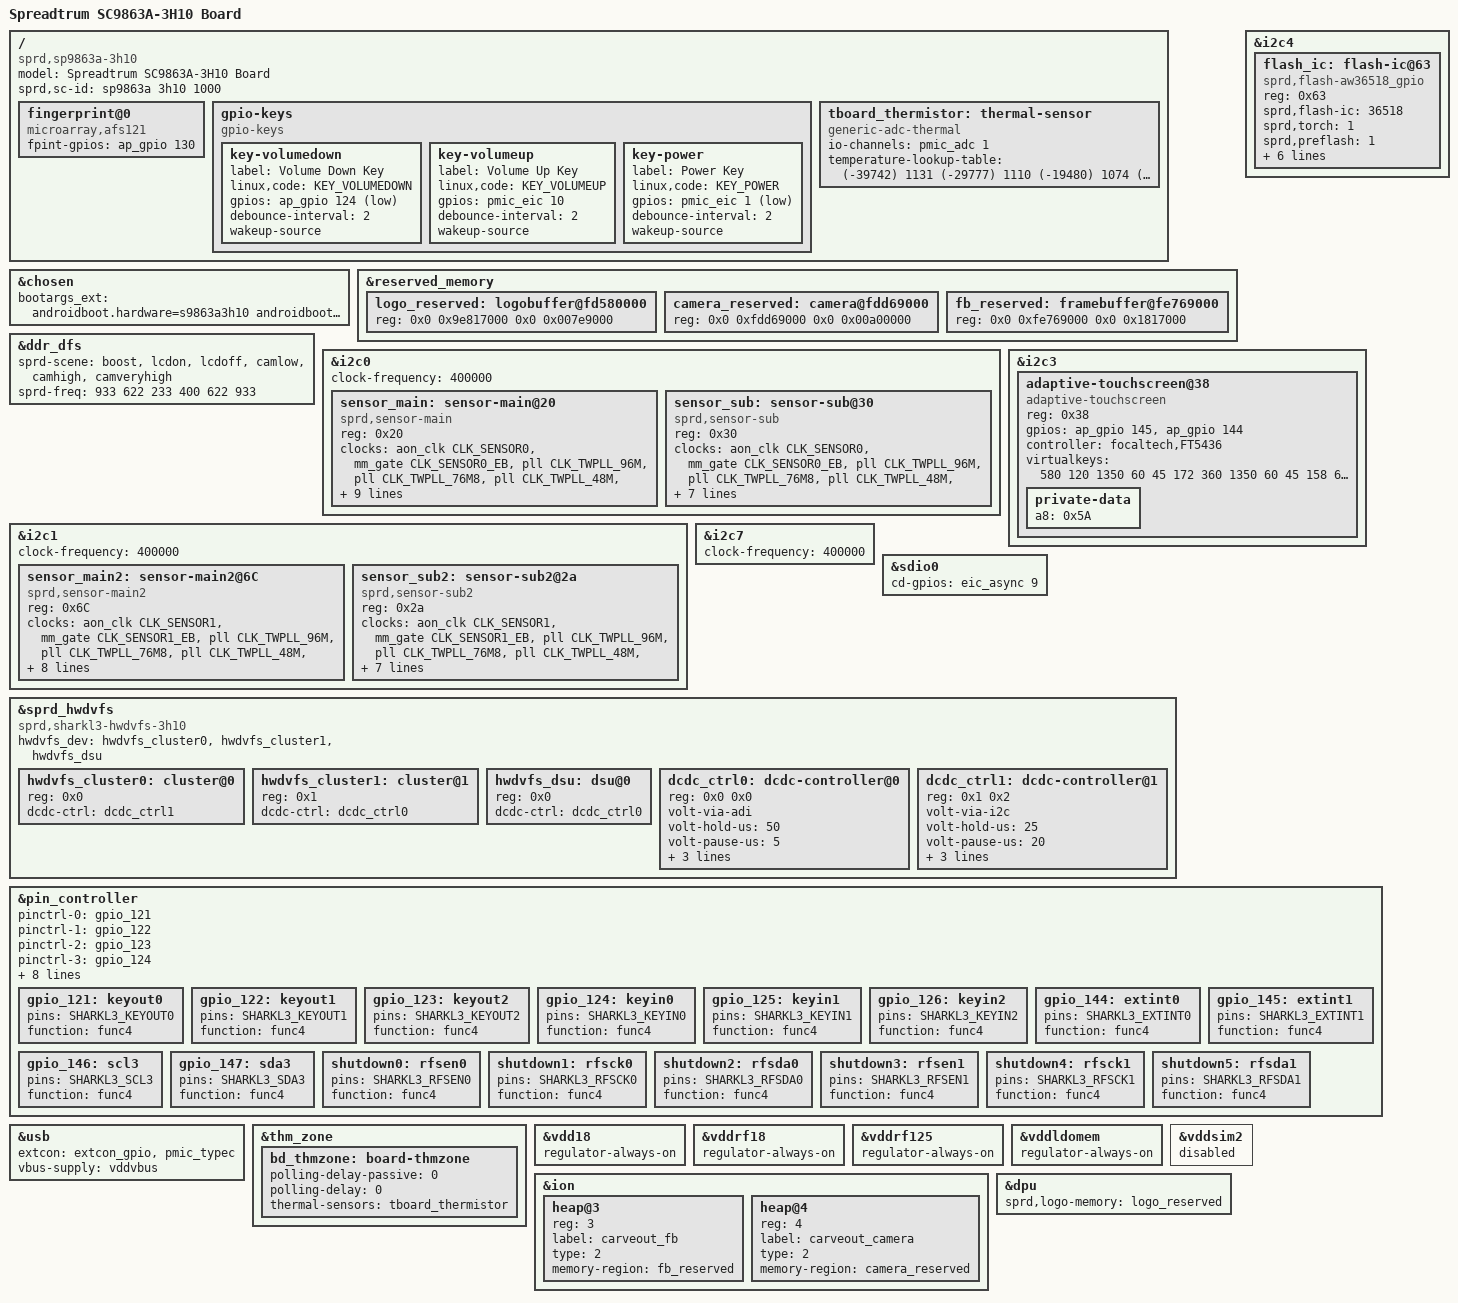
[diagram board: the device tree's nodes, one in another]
/dts-v1/;
/plugin/;

#include <dt-bindings/input/input.h>
#include <dt-bindings/gpio/gpio.h>
#include <dt-bindings/clock/sprd,sc9863a-clk.h>
/ {
	model = "Spreadtrum SC9863A-3H10 Board";
	compatible = "sprd,sp9863a-3h10", "sprd,sc9863a";
	sprd,sc-id = "sp9863a 3h10 1000";

	fragment {
		target-path = "/";
		__overlay__ {
			fingerprint@0 {
				compatible = "microarray,afs121";
				fpint-gpios = <&ap_gpio 130 0>;
			};

			gpio-keys {
				compatible = "gpio-keys";

				key-volumedown {
					label = "Volume Down Key";
					linux,code = <KEY_VOLUMEDOWN>;
					gpios = <&ap_gpio 124 GPIO_ACTIVE_LOW>;
					debounce-interval = <2>;
					wakeup-source;
				};

				key-volumeup {
					label = "Volume Up Key";
					linux,code = <KEY_VOLUMEUP>;
					gpios = <&pmic_eic 10 GPIO_ACTIVE_HIGH>;
					debounce-interval = <2>;
					wakeup-source;
				};

				key-power {
					label = "Power Key";
					linux,code = <KEY_POWER>;
					gpios = <&pmic_eic 1 GPIO_ACTIVE_LOW>;
					debounce-interval = <2>;
					wakeup-source;
				};
			};

			tboard_thermistor:thermal-sensor {
				compatible = "generic-adc-thermal";
				#thermal-sensor-cells = <0>;
				io-channels = <&pmic_adc 1>;
				io-channel-names = "sensor-channel";
				temperature-lookup-table = <	(-39742) 1131
								(-29777) 1110
								(-19480) 1074
								(-4679) 983
								10110 838
								24805 654
								44922 413
								54903 316
								64895 238
								74884 178
								84883 133
								94883 100
								104880 75
								114889 57
								124872 43 >;
			};
		};
	};
};

&chosen {
	bootargs_ext = "androidboot.hardware=s9863a3h10 androidboot.dtbo_idx=0";
};

&reserved_memory {

	logo_reserved: logobuffer@fd580000{
		reg = <0x0 0xfd580000 0x0 0x007e9000>;
	};

	camera_reserved: camera@fdd69000{
		reg = <0x0 0xfdd69000 0x0 0x00a00000>;
	};

	fb_reserved: framebuffer@fe769000 {
		reg = <0x0 0xfe769000 0x0 0x1817000>;
	};
};

&ddr_dfs {
	sprd-scene = "boost", "lcdon", "lcdoff", "camlow",
			"camhigh", "camveryhigh";
	sprd-freq = <933 622 233 400 622 933>;
};

&i2c4 {
	flash_ic: flash-ic@63 {
		compatible = "sprd,flash-aw36518_gpio";
		reg = <0x63>;
		sprd,flash-ic = <36518>;
		sprd,torch = <1>;
		sprd,preflash = <1>;
		sprd,highlight = <1>;
		sprd,torch-level = <10>;
		sprd,preflash-level = <10>;
		sprd,highlight-level = <15>;
		sprd,lvfm-enable = <1>;
		flash-torch-en-gpios = <&ap_gpio 89 0>;
	};
};

&i2c0 {
	status = "okay";
	clock-frequency = <400000>;

	sensor_main: sensor-main@20 {
		compatible = "sprd,sensor-main";
		reg = <0x20>;
		clock-names = "clk_src","sensor_eb",
			"clk_96m","clk_76m8",
			"clk_48m","clk_26m";
		clocks = <&aon_clk CLK_SENSOR0>, <&mm_gate CLK_SENSOR0_EB>,
			<&pll CLK_TWPLL_96M>,<&pll CLK_TWPLL_76M8>,
			<&pll CLK_TWPLL_48M>,<&ext_26m>;
		vddio-supply = <&vddcamio>;
		avdd-gpios=<&ap_gpio 97 0>;
		vddcamd-supply = <&vddcamd>;
		vddcammot-supply = <&vddcammot>;
		sprd,phyid = <1>;
		csi = <&csi0>;
		reset-gpios = <&ap_gpio 44 0>;
		power-down-gpios = <&ap_gpio 46 0>;
	};

	sensor_sub: sensor-sub@30 {
	compatible = "sprd,sensor-sub";
		reg = <0x30>;
		clock-names = "clk_src","sensor_eb",
			"clk_96m","clk_76m8",
			"clk_48m","clk_26m";
		clocks = <&aon_clk CLK_SENSOR0>, <&mm_gate CLK_SENSOR0_EB>,
			<&pll CLK_TWPLL_96M>,<&pll CLK_TWPLL_76M8>,
			<&pll CLK_TWPLL_48M>,<&ext_26m>;
		vddio-supply = <&vddcamio>;
		avdd-gpios=<&ap_gpio 85 0>;
		vddcamd-supply = <&vddcamd>;
		sprd,phyid = <3>;
		csi = <&csi1>;
		reset-gpios = <&ap_gpio 41 0>;
		//power-down-gpios = <&ap_gpio 42 0>;
	};
};

&i2c1 {
	status = "okay";
	clock-frequency = <400000>;

	sensor_main2: sensor-main2@6C {
		compatible = "sprd,sensor-main2";
		reg = <0x6C>;
		clock-names = "clk_src","sensor_eb",
			"clk_96m","clk_76m8",
			"clk_48m","clk_26m";
		clocks = <&aon_clk CLK_SENSOR1>, <&mm_gate CLK_SENSOR1_EB>,
			<&pll CLK_TWPLL_96M>,<&pll CLK_TWPLL_76M8>,
			<&pll CLK_TWPLL_48M>,<&ext_26m>;
		vddio-supply = <&vddcamio>;
		vddcama-supply = <&vddcama>;
		vddcamd-supply = <&vddcamd>;
		sprd,phyid = <2>;
		csi = <&csi1>;
		reset-gpios = <&ap_gpio 45 0>;
		power-down-gpios = <&ap_gpio 88 0>;
	};

	sensor_sub2: sensor-sub2@2a {
		compatible = "sprd,sensor-sub2";
		reg = <0x2a>;
		clock-names = "clk_src","sensor_eb",
			"clk_96m","clk_76m8",
			"clk_48m","clk_26m";
		clocks = <&aon_clk CLK_SENSOR1>, <&mm_gate CLK_SENSOR1_EB>,
			<&pll CLK_TWPLL_96M>,<&pll CLK_TWPLL_76M8>,
			<&pll CLK_TWPLL_48M>,<&ext_26m>;
		vddio-supply = <&vddcamio>;
		vddcama-supply = <&vddcama>;
		vddcamd-supply = <&vddcamd>;
		sprd,phyid = <4>;
		csi = <&csi1>;
		reset-gpios = <&ap_gpio 40 0>;
		//power-down-gpios = <&ap_gpio 47 0>;
	};
};

&i2c3 {
	status = "okay";

	adaptive-touchscreen@38 {
		compatible = "adaptive-touchscreen";
		reg = <0x38>;
		gpios = <&ap_gpio 145 GPIO_ACTIVE_HIGH
			&ap_gpio 144 GPIO_ACTIVE_HIGH>;
		controller = "focaltech,FT5436";
		virtualkeys = <580 120 1350 60 45
			172 360 1350 60 45
			158 600 1350 60 45>;
		private-data {
			a8 = /bits/ 8 <0x5A>;
		};
	};
};

&i2c7 {
	status = "okay";
	clock-frequency = <400000>;
};


&sdio0 {
	cd-gpios = <&eic_async 9 0>;
};

&sprd_hwdvfs {
	compatible = "sprd,sharkl3-hwdvfs-3h10";

	hwdvfs_dev = <&hwdvfs_cluster0>,
		<&hwdvfs_cluster1>,
		<&hwdvfs_dsu>;

	hwdvfs_cluster0: cluster@0 {
		reg = <0x0>;
		dcdc-ctrl = <&dcdc_ctrl1>;
	};

	hwdvfs_cluster1: cluster@1 {
		reg = <0x1>;
		dcdc-ctrl = <&dcdc_ctrl0>;
	};

	hwdvfs_dsu: dsu@0 {
		reg = <0x0>;
		dcdc-ctrl = <&dcdc_ctrl0>;
	};

	dcdc_ctrl0: dcdc-controller@0 {
		reg = <0x0 0x0>;
		volt-via-adi;
		volt-hold-us = <50>;
		volt-pause-us = <5>;
		volt-timeout-us = <800>;
		volt-stable-us  = <5>;
		volt-max-step-microvolt = <25000>;
	};

	dcdc_ctrl1: dcdc-controller@1 {
		reg = <0x1 0x2>;
		volt-via-i2c;
		volt-hold-us = <25>;
		volt-pause-us = <20>;
		volt-timeout-us = <800>;
		volt-stable-us  = <25>;
		volt-max-step-microvolt = <1200004>;
	};
};

&pin_controller {
	pinctrl-names =
	/* keyout0 ~ keyout2 */
	"gpio_121", "gpio_122", "gpio_123",
	/* keyin0 ~ keyin2 */
	"gpio_124", "gpio_125", "gpio_126",
	/* extint0, extint1, scl3, sda3 */
	"gpio_144", "gpio_145", "gpio_146", "gpio_147",
	/* Note:If create a new board,need to add the shutdown node */
	"shutdown";
	pinctrl-0 = <&gpio_121>;
	pinctrl-1 = <&gpio_122>;
	pinctrl-2 = <&gpio_123>;
	pinctrl-3 = <&gpio_124>;
	pinctrl-4 = <&gpio_125>;
	pinctrl-5 = <&gpio_126>;
	pinctrl-6 = <&gpio_144>;
	pinctrl-7 = <&gpio_145>;
	pinctrl-8 = <&gpio_146>;
	pinctrl-9 = <&gpio_147>;
	pinctrl-10 = <&shutdown0
			&shutdown1
			&shutdown2
			&shutdown3
			&shutdown4
			&shutdown5>;

	gpio_121: keyout0 {
		pins = "SHARKL3_KEYOUT0";
		function = "func4";
	};

	gpio_122: keyout1 {
		pins = "SHARKL3_KEYOUT1";
		function = "func4";
	};

	gpio_123: keyout2 {
		pins = "SHARKL3_KEYOUT2";
		function = "func4";
	};

	gpio_124: keyin0 {
		pins = "SHARKL3_KEYIN0";
		function = "func4";
	};

	gpio_125: keyin1 {
		pins = "SHARKL3_KEYIN1";
		function = "func4";
	};

	gpio_126: keyin2 {
		pins = "SHARKL3_KEYIN2";
		function = "func4";
	};

	gpio_144: extint0 {
		pins = "SHARKL3_EXTINT0";
		function = "func4";
	};

	gpio_145: extint1 {
		pins = "SHARKL3_EXTINT1";
		function = "func4";
	};

	gpio_146: scl3 {
		pins = "SHARKL3_SCL3";
		function = "func4";
	};

	gpio_147: sda3 {
		pins = "SHARKL3_SDA3";
		function = "func4";
	};

	shutdown0: rfsen0 {
		pins = "SHARKL3_RFSEN0";
		function = "func4";
	};

	shutdown1: rfsck0 {
		pins = "SHARKL3_RFSCK0";
		function = "func4";
	};

	shutdown2: rfsda0 {
		pins = "SHARKL3_RFSDA0";
		function = "func4";
	};

	shutdown3: rfsen1 {
		pins = "SHARKL3_RFSEN1";
		function = "func4";
	};

	shutdown4: rfsck1 {
		pins = "SHARKL3_RFSCK1";
		function = "func4";
	};

	shutdown5: rfsda1 {
		pins = "SHARKL3_RFSDA1";
		function = "func4";
	};
};

&usb {
	extcon = <&extcon_gpio>, <&pmic_typec>;
	vbus-supply = <&vddvbus>;
};

&thm_zone {
	bd_thmzone: board-thmzone {
		polling-delay-passive = <0>;
		polling-delay = <0>;
		thermal-sensors = <&tboard_thermistor>;
	};
};

&vdd18 {
	regulator-always-on;
};

&vddrf18 {
	regulator-always-on;
};

&vddrf125 {
	regulator-always-on;
};

&vddldomem {
	regulator-always-on;
};

&vddsim2 {
	status = "disabled";
};

&logo_reserved {
	reg = <0x0 0x9e817000 0x0 0x007e9000>;
};

&ion {
	heap@3 {
			reg = <3>;
			label = "carveout_fb";
			type = <2>;
			memory-region = <&fb_reserved>;
	};

	heap@4 {
			reg = <4>;
			label = "carveout_camera";
			type = <2>;
			memory-region = <&camera_reserved>;
	};
};

&dpu {
	sprd,logo-memory = <&logo_reserved>;
};
